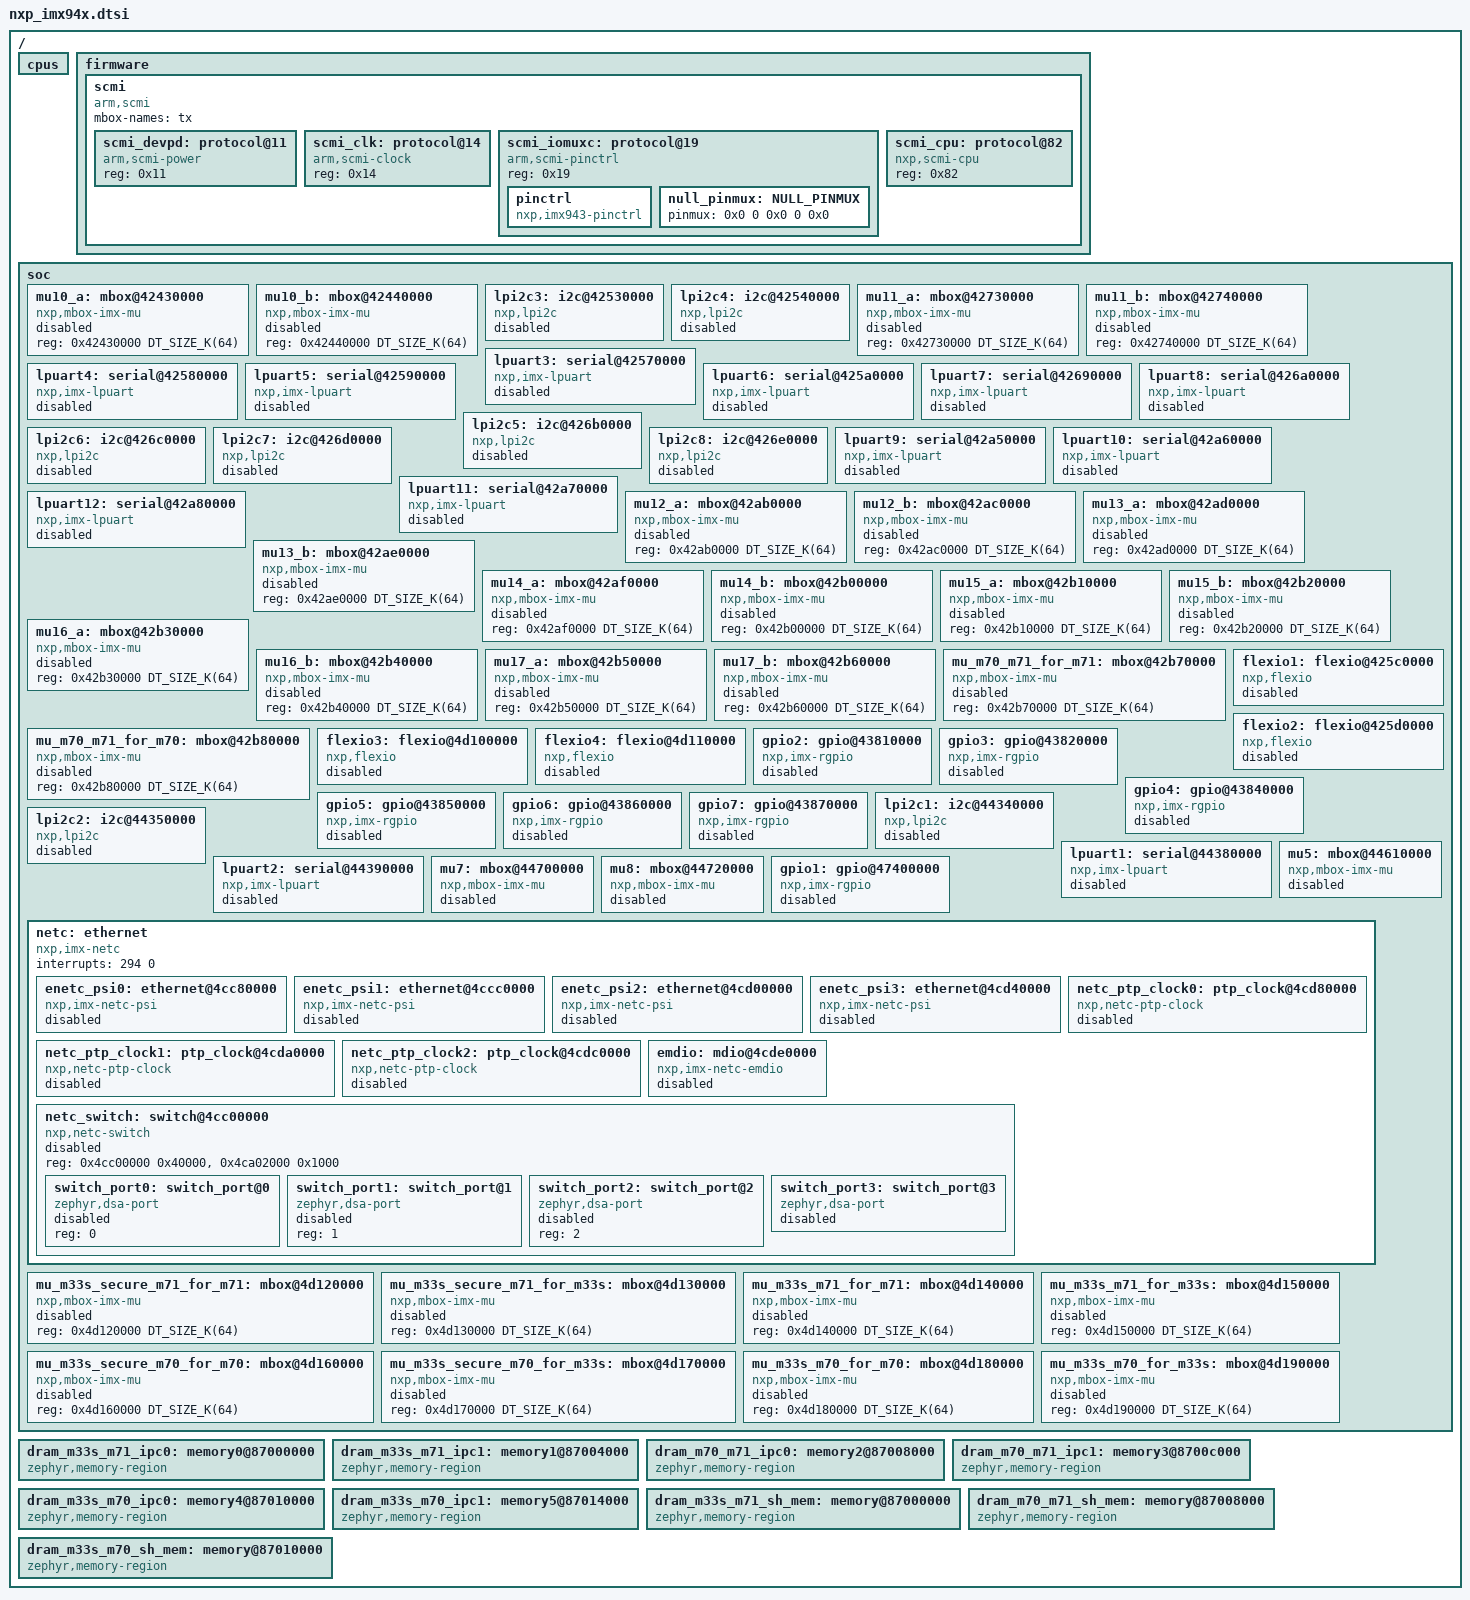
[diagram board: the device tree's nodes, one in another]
/*
 * Copyright 2025 NXP
 *
 * SPDX-License-Identifier: Apache-2.0
 */

#include <mem.h>
#include <dt-bindings/i2c/i2c.h>
#include <zephyr/dt-bindings/clock/imx943_clock.h>
#include <zephyr/dt-bindings/ethernet/dsa_tag_proto.h>
#include <zephyr/dt-bindings/gpio/gpio.h>
#include <zephyr/dt-bindings/memory-attr/memory-attr-arm.h>

/ {
	cpus {
		#address-cells = <1>;
		#size-cells = <0>;
	};

	firmware {
		scmi: scmi {
			compatible = "arm,scmi";
			mbox-names = "tx";

			#address-cells = <1>;
			#size-cells = <0>;

			scmi_devpd: protocol@11 {
				compatible = "arm,scmi-power";
				reg = <0x11>;
				#power-domain-cells = <1>;
			};

			scmi_clk: protocol@14 {
				compatible = "arm,scmi-clock";
				reg = <0x14>;
				#clock-cells = <1>;
			};

			scmi_iomuxc: protocol@19 {
				compatible = "arm,scmi-pinctrl";
				reg = <0x19>;

				pinctrl: pinctrl {
					compatible = "nxp,imx943-pinctrl", "nxp,imx93-pinctrl";
				};
				/*
				 * Use the NULL pinmux for the GPIO io port
				 * which is not available to
				 * make the driver to be easy.
				 */
				/omit-if-no-ref/ null_pinmux: NULL_PINMUX {
					pinmux = <0x0 0 0x0 0 0x0>;
				};
			};

			scmi_cpu: protocol@82 {
				compatible = "nxp,scmi-cpu";
				reg = <0x82>;
			};
		};
	};

	soc {
		mu10_a: mbox@42430000 {
			compatible = "nxp,mbox-imx-mu";
			reg = <0x42430000 DT_SIZE_K(64)>;
			#mbox-cells = <1>;
			status = "disabled";
		};

		mu10_b: mbox@42440000 {
			compatible = "nxp,mbox-imx-mu";
			reg = <0x42440000 DT_SIZE_K(64)>;
			#mbox-cells = <1>;
			status = "disabled";
		};

		lpi2c3: i2c@42530000 {
			compatible = "nxp,lpi2c";
			clock-frequency = <I2C_BITRATE_STANDARD>;
			#address-cells = <1>;
			#size-cells = <0>;
			reg = <0x42530000 0x4000>;
			interrupts = <67 0>;
			clocks = <&scmi_clk IMX943_CLK_LPI2C3>;
			status = "disabled";
		};

		lpi2c4: i2c@42540000 {
			compatible = "nxp,lpi2c";
			clock-frequency = <I2C_BITRATE_STANDARD>;
			#address-cells = <1>;
			#size-cells = <0>;
			reg = <0x42540000 0x4000>;
			interrupts = <68 0>;
			clocks = <&scmi_clk IMX943_CLK_LPI2C4>;
			status = "disabled";
		};

		mu11_a: mbox@42730000 {
			compatible = "nxp,mbox-imx-mu";
			reg = <0x42730000 DT_SIZE_K(64)>;
			#mbox-cells = <1>;
			status = "disabled";
		};

		mu11_b: mbox@42740000 {
			compatible = "nxp,mbox-imx-mu";
			reg = <0x42740000 DT_SIZE_K(64)>;
			#mbox-cells = <1>;
			status = "disabled";
		};

		lpuart3: serial@42570000 {
			compatible = "nxp,imx-lpuart", "nxp,lpuart";
			reg = <0x42570000 DT_SIZE_K(64)>;
			interrupts = <74 3>;
			clocks = <&scmi_clk IMX943_CLK_LPUART3>;
			status = "disabled";
		};

		lpuart4: serial@42580000 {
			compatible = "nxp,imx-lpuart", "nxp,lpuart";
			reg = <0x42580000 DT_SIZE_K(64)>;
			interrupts = <75 3>;
			clocks = <&scmi_clk IMX943_CLK_LPUART4>;
			status = "disabled";
		};

		lpuart5: serial@42590000 {
			compatible = "nxp,imx-lpuart", "nxp,lpuart";
			reg = <0x42590000 DT_SIZE_K(64)>;
			interrupts = <76 3>;
			clocks = <&scmi_clk IMX943_CLK_LPUART5>;
			status = "disabled";
		};

		lpuart6: serial@425a0000 {
			compatible = "nxp,imx-lpuart", "nxp,lpuart";
			reg = <0x425a0000 DT_SIZE_K(64)>;
			interrupts = <77 3>;
			clocks = <&scmi_clk IMX943_CLK_LPUART6>;
			status = "disabled";
		};

		lpuart7: serial@42690000 {
			compatible = "nxp,imx-lpuart", "nxp,lpuart";
			reg = <0x42690000 DT_SIZE_K(64)>;
			interrupts = <78 3>;
			clocks = <&scmi_clk IMX943_CLK_LPUART7>;
			status = "disabled";
		};

		lpuart8: serial@426a0000 {
			compatible = "nxp,imx-lpuart", "nxp,lpuart";
			reg = <0x426a0000 DT_SIZE_K(64)>;
			interrupts = <79 3>;
			clocks = <&scmi_clk IMX943_CLK_LPUART8>;
			status = "disabled";
		};

		lpi2c5: i2c@426b0000 {
			compatible = "nxp,lpi2c";
			clock-frequency = <I2C_BITRATE_STANDARD>;
			#address-cells = <1>;
			#size-cells = <0>;
			reg = <0x426b0000 0x4000>;
			interrupts = <108 0>;
			clocks = <&scmi_clk IMX943_CLK_LPI2C5>;
			status = "disabled";
		};

		lpi2c6: i2c@426c0000 {
			compatible = "nxp,lpi2c";
			clock-frequency = <I2C_BITRATE_STANDARD>;
			#address-cells = <1>;
			#size-cells = <0>;
			reg = <0x426c0000 0x4000>;
			interrupts = <109 0>;
			clocks = <&scmi_clk IMX943_CLK_LPI2C6>;
			status = "disabled";
		};

		lpi2c7: i2c@426d0000 {
			compatible = "nxp,lpi2c";
			clock-frequency = <I2C_BITRATE_STANDARD>;
			#address-cells = <1>;
			#size-cells = <0>;
			reg = <0x426d0000 0x4000>;
			interrupts = <110 0>;
			clocks = <&scmi_clk IMX943_CLK_LPI2C7>;
			status = "disabled";
		};

		lpi2c8: i2c@426e0000 {
			compatible = "nxp,lpi2c";
			clock-frequency = <I2C_BITRATE_STANDARD>;
			#address-cells = <1>;
			#size-cells = <0>;
			reg = <0x426e0000 0x4000>;
			interrupts = <111 0>;
			clocks = <&scmi_clk IMX943_CLK_LPI2C8>;
			status = "disabled";
		};

		lpuart9: serial@42a50000 {
			compatible = "nxp,imx-lpuart", "nxp,lpuart";
			reg = <0x42a50000 DT_SIZE_K(64)>;
			interrupts = <80 3>;
			clocks = <&scmi_clk IMX943_CLK_LPUART9>;
			status = "disabled";
		};

		lpuart10: serial@42a60000 {
			compatible = "nxp,imx-lpuart", "nxp,lpuart";
			reg = <0x42a60000 DT_SIZE_K(64)>;
			interrupts = <81 3>;
			clocks = <&scmi_clk IMX943_CLK_LPUART10>;
			status = "disabled";
		};

		lpuart11: serial@42a70000 {
			compatible = "nxp,imx-lpuart", "nxp,lpuart";
			reg = <0x42a70000 DT_SIZE_K(64)>;
			interrupts = <82 3>;
			clocks = <&scmi_clk IMX943_CLK_LPUART11>;
			status = "disabled";
		};

		lpuart12: serial@42a80000 {
			compatible = "nxp,imx-lpuart", "nxp,lpuart";
			reg = <0x42a80000 DT_SIZE_K(64)>;
			interrupts = <83 3>;
			clocks = <&scmi_clk IMX943_CLK_LPUART12>;
			status = "disabled";
		};

		mu12_a: mbox@42ab0000 {
			compatible = "nxp,mbox-imx-mu";
			reg = <0x42ab0000 DT_SIZE_K(64)>;
			#mbox-cells = <1>;
			status = "disabled";
		};

		mu12_b: mbox@42ac0000 {
			compatible = "nxp,mbox-imx-mu";
			reg = <0x42ac0000 DT_SIZE_K(64)>;
			#mbox-cells = <1>;
			status = "disabled";
		};

		mu13_a: mbox@42ad0000 {
			compatible = "nxp,mbox-imx-mu";
			reg = <0x42ad0000 DT_SIZE_K(64)>;
			#mbox-cells = <1>;
			status = "disabled";
		};

		mu13_b: mbox@42ae0000 {
			compatible = "nxp,mbox-imx-mu";
			reg = <0x42ae0000 DT_SIZE_K(64)>;
			#mbox-cells = <1>;
			status = "disabled";
		};

		mu14_a: mbox@42af0000 {
			compatible = "nxp,mbox-imx-mu";
			reg = <0x42af0000 DT_SIZE_K(64)>;
			#mbox-cells = <1>;
			status = "disabled";
		};

		mu14_b: mbox@42b00000 {
			compatible = "nxp,mbox-imx-mu";
			reg = <0x42b00000 DT_SIZE_K(64)>;
			#mbox-cells = <1>;
			status = "disabled";
		};

		mu15_a: mbox@42b10000 {
			compatible = "nxp,mbox-imx-mu";
			reg = <0x42b10000 DT_SIZE_K(64)>;
			#mbox-cells = <1>;
			status = "disabled";
		};

		mu15_b: mbox@42b20000 {
			compatible = "nxp,mbox-imx-mu";
			reg = <0x42b20000 DT_SIZE_K(64)>;
			#mbox-cells = <1>;
			status = "disabled";
		};

		mu16_a: mbox@42b30000 {
			compatible = "nxp,mbox-imx-mu";
			reg = <0x42b30000 DT_SIZE_K(64)>;
			#mbox-cells = <1>;
			status = "disabled";
		};

		mu16_b: mbox@42b40000 {
			compatible = "nxp,mbox-imx-mu";
			reg = <0x42b40000 DT_SIZE_K(64)>;
			#mbox-cells = <1>;
			status = "disabled";
		};

		mu17_a: mbox@42b50000 {
			compatible = "nxp,mbox-imx-mu";
			reg = <0x42b50000 DT_SIZE_K(64)>;
			#mbox-cells = <1>;
			status = "disabled";
		};

		mu17_b: mbox@42b60000 {
			compatible = "nxp,mbox-imx-mu";
			reg = <0x42b60000 DT_SIZE_K(64)>;
			#mbox-cells = <1>;
			status = "disabled";
		};

		mu_m70_m71_for_m71: mbox@42b70000 {
			compatible = "nxp,mbox-imx-mu";
			reg = <0x42b70000 DT_SIZE_K(64)>;
			#mbox-cells = <1>;
			status = "disabled";
		};

		mu_m70_m71_for_m70: mbox@42b80000 {
			compatible = "nxp,mbox-imx-mu";
			reg = <0x42b80000 DT_SIZE_K(64)>;
			#mbox-cells = <1>;
			status = "disabled";
		};

		flexio1: flexio@425c0000 {
			compatible = "nxp,flexio";
			reg = <0x425c0000 DT_SIZE_K(4)>;
			interrupts = <48 0>;
			clocks = <&scmi_clk IMX943_CLK_FLEXIO1>;
			status = "disabled";
		};

		flexio2: flexio@425d0000 {
			compatible = "nxp,flexio";
			reg = <0x425d0000 DT_SIZE_K(4)>;
			interrupts = <49 0>;
			clocks = <&scmi_clk IMX943_CLK_FLEXIO2>;
			status = "disabled";
		};

		flexio3: flexio@4d100000 {
			compatible = "nxp,flexio";
			reg = <0x4d100000 DT_SIZE_K(4)>;
			interrupts = <50 0>;
			clocks = <&scmi_clk IMX943_CLK_FLEXIO3>;
			status = "disabled";
		};

		flexio4: flexio@4d110000 {
			compatible = "nxp,flexio";
			reg = <0x4d110000 DT_SIZE_K(4)>;
			interrupts = <51 0>;
			clocks = <&scmi_clk IMX943_CLK_FLEXIO4>;
			status = "disabled";
		};

		gpio2: gpio@43810000 {
			compatible = "nxp,imx-rgpio";
			reg = <0x43810000 DT_SIZE_K(64)>;
			interrupts = <54 0>, <55 0>;
			gpio-controller;
			#gpio-cells = <2>;
			ngpios = <32>;
			status = "disabled";
		};

		gpio3: gpio@43820000 {
			compatible = "nxp,imx-rgpio";
			reg = <0x43820000 DT_SIZE_K(64)>;
			interrupts = <56 0>, <57 0>;
			gpio-controller;
			#gpio-cells = <2>;
			ngpios = <26>;
			status = "disabled";
		};

		gpio4: gpio@43840000 {
			compatible = "nxp,imx-rgpio";
			reg = <0x43840000 DT_SIZE_K(64)>;
			interrupts = <58 0>, <59 0>;
			gpio-controller;
			#gpio-cells = <2>;
			ngpios = <32>;
			status = "disabled";
		};

		gpio5: gpio@43850000 {
			compatible = "nxp,imx-rgpio";
			reg = <0x43850000 DT_SIZE_K(64)>;
			interrupts = <60 0>, <61 0>;
			gpio-controller;
			#gpio-cells = <2>;
			ngpios = <32>;
			status = "disabled";
		};

		gpio6: gpio@43860000 {
			compatible = "nxp,imx-rgpio";
			reg = <0x43860000 DT_SIZE_K(64)>;
			interrupts = <62 0>, <63 0>;
			gpio-controller;
			#gpio-cells = <2>;
			ngpios = <32>;
			status = "disabled";
		};

		gpio7: gpio@43870000 {
			compatible = "nxp,imx-rgpio";
			reg = <0x43870000 DT_SIZE_K(64)>;
			interrupts = <64 0>, <65 0>;
			gpio-controller;
			#gpio-cells = <2>;
			ngpios = <28>;
			gpio-reserved-ranges = <10 6>;
			status = "disabled";
		};

		lpi2c1: i2c@44340000 {
			compatible = "nxp,lpi2c";
			clock-frequency = <I2C_BITRATE_STANDARD>;
			#address-cells = <1>;
			#size-cells = <0>;
			reg = <0x44340000 0x4000>;
			interrupts = <15 0>;
			clocks = <&scmi_clk IMX943_CLK_LPI2C1>;
			status = "disabled";
		};

		lpi2c2: i2c@44350000 {
			compatible = "nxp,lpi2c";
			clock-frequency = <I2C_BITRATE_STANDARD>;
			#address-cells = <1>;
			#size-cells = <0>;
			reg = <0x44350000 0x4000>;
			interrupts = <16 0>;
			clocks = <&scmi_clk IMX943_CLK_LPI2C2>;
			status = "disabled";
		};

		lpuart1: serial@44380000 {
			compatible = "nxp,imx-lpuart", "nxp,lpuart";
			reg = <0x44380000 DT_SIZE_K(64)>;
			interrupts = <21 3>;
			clocks = <&scmi_clk IMX943_CLK_LPUART1>;
			status = "disabled";
		};

		lpuart2: serial@44390000 {
			compatible = "nxp,imx-lpuart", "nxp,lpuart";
			reg = <0x44390000 DT_SIZE_K(64)>;
			interrupts = <22 3>;
			clocks = <&scmi_clk IMX943_CLK_LPUART2>;
			status = "disabled";
		};

		mu5: mbox@44610000 {
			compatible = "nxp,mbox-imx-mu";
			reg = <0x44610000 DT_SIZE_K(64)>;
			interrupts = <122 0>;
			#mbox-cells = <1>;
			status = "disabled";
		};

		mu7: mbox@44700000 {
			compatible = "nxp,mbox-imx-mu";
			reg = <0x44700000 DT_SIZE_K(64)>;
			interrupts = <124 0>;
			#mbox-cells = <1>;
			status = "disabled";
		};

		mu8: mbox@44720000 {
			compatible = "nxp,mbox-imx-mu";
			reg = <0x44720000 DT_SIZE_K(64)>;
			interrupts = <273 0>;
			#mbox-cells = <1>;
			status = "disabled";
		};

		gpio1: gpio@47400000 {
			compatible = "nxp,imx-rgpio";
			reg = <0x47400000 DT_SIZE_K(64)>;
			interrupts = <12 0>, <13 0>;
			gpio-controller;
			#gpio-cells = <2>;
			ngpios = <16>;
			status = "disabled";
		};

		netc: ethernet {
			compatible = "nxp,imx-netc";
			interrupts = <294 0>;
			#address-cells = <1>;
			#size-cells = <1>;
			ranges;

			enetc_psi0: ethernet@4cc80000 {
				compatible = "nxp,imx-netc-psi";
				reg = <0x4cc80000 0x10000>,
				      <0x4cb00000 0x1000>;
				reg-names = "port", "pfconfig";
				mac-index = <0>;
				si-index = <0>;
				status = "disabled";
			};

			enetc_psi1: ethernet@4ccc0000 {
				compatible = "nxp,imx-netc-psi";
				reg = <0x4ccc0000 0x10000>,
				      <0x4cb40000 0x1000>;
				reg-names = "port", "pfconfig";
				mac-index = <1>;
				si-index = <1>;
				status = "disabled";
			};

			enetc_psi2: ethernet@4cd00000 {
				compatible = "nxp,imx-netc-psi";
				reg = <0x4cd00000 0x10000>,
				      <0x4cb80000 0x1000>;
				reg-names = "port", "pfconfig";
				mac-index = <2>;
				si-index = <2>;
				status = "disabled";
			};

			/* Internal port */
			enetc_psi3: ethernet@4cd40000 {
				compatible = "nxp,imx-netc-psi";
				reg = <0x4cd40000 0x10000>,
				      <0x4ca00000 0x1000>;
				reg-names = "port", "pfconfig";
				mac-index = <3>;
				si-index = <3>;
				phy-connection-type = "internal";
				status = "disabled";
			};

			netc_ptp_clock0: ptp_clock@4cd80000 {
				compatible = "nxp,netc-ptp-clock";
				reg = <0x4cd80000 0x10000>;
				clocks = <&scmi_clk IMX943_CLK_ENET>;
				status = "disabled";
			};

			netc_ptp_clock1: ptp_clock@4cda0000 {
				compatible = "nxp,netc-ptp-clock";
				reg = <0x4cda0000 0x10000>;
				clocks = <&scmi_clk IMX943_CLK_ENET>;
				status = "disabled";
			};

			netc_ptp_clock2: ptp_clock@4cdc0000 {
				compatible = "nxp,netc-ptp-clock";
				reg = <0x4cdc0000 0x10000>;
				clocks = <&scmi_clk IMX943_CLK_ENET>;
				status = "disabled";
			};

			emdio: mdio@4cde0000 {
				compatible = "nxp,imx-netc-emdio";
				reg = <0x4cde0000 0x10000>,
					<0x4cbc0000 0x40000>;
				reg-names = "basic", "pfconfig";
				clocks = <&scmi_clk IMX943_CLK_ENET>;
				#address-cells = <1>;
				#size-cells = <0>;
				status = "disabled";
			};

			netc_switch: switch@4cc00000 {
				compatible = "nxp,netc-switch";
				reg = <0x4cc00000 0x40000>,
				      <0x4ca02000 0x1000>;
				reg-names = "base", "pfconfig";
				status = "disabled";
				#address-cells = <1>;
				#size-cells = <0>;

				switch_port0: switch_port@0 {
					compatible = "zephyr,dsa-port";
					reg = <0>;
					status = "disabled";
				};

				switch_port1: switch_port@1 {
					compatible = "zephyr,dsa-port";
					reg = <1>;
					status = "disabled";
				};

				/* Parallel interface is muxed with enetc_psi0. */
				switch_port2: switch_port@2 {
					compatible = "zephyr,dsa-port";
					reg = <2>;
					status = "disabled";
				};

				/* Internal port */
				switch_port3: switch_port@3 {
					compatible = "zephyr,dsa-port";
					reg = <3>;
					ethernet = <&enetc_psi3>;
					phy-connection-type = "internal";
					dsa-tag-protocol = <DSA_TAG_PROTO_NETC>;
					status = "disabled";
				};
			};
		};

		mu_m33s_secure_m71_for_m71: mbox@4d120000 {
			compatible = "nxp,mbox-imx-mu";
			reg = <0x4d120000 DT_SIZE_K(64)>;
			#mbox-cells = <1>;
			status = "disabled";
		};

		mu_m33s_secure_m71_for_m33s: mbox@4d130000 {
			compatible = "nxp,mbox-imx-mu";
			reg = <0x4d130000 DT_SIZE_K(64)>;
			#mbox-cells = <1>;
			status = "disabled";
		};

		mu_m33s_m71_for_m71: mbox@4d140000 {
			compatible = "nxp,mbox-imx-mu";
			reg = <0x4d140000 DT_SIZE_K(64)>;
			#mbox-cells = <1>;
			status = "disabled";
		};

		mu_m33s_m71_for_m33s: mbox@4d150000 {
			compatible = "nxp,mbox-imx-mu";
			reg = <0x4d150000 DT_SIZE_K(64)>;
			#mbox-cells = <1>;
			status = "disabled";
		};

		mu_m33s_secure_m70_for_m70: mbox@4d160000 {
			compatible = "nxp,mbox-imx-mu";
			reg = <0x4d160000 DT_SIZE_K(64)>;
			#mbox-cells = <1>;
			status = "disabled";
		};

		mu_m33s_secure_m70_for_m33s: mbox@4d170000 {
			compatible = "nxp,mbox-imx-mu";
			reg = <0x4d170000 DT_SIZE_K(64)>;
			#mbox-cells = <1>;
			status = "disabled";
		};

		mu_m33s_m70_for_m70: mbox@4d180000 {
			compatible = "nxp,mbox-imx-mu";
			reg = <0x4d180000 DT_SIZE_K(64)>;
			#mbox-cells = <1>;
			status = "disabled";
		};

		mu_m33s_m70_for_m33s: mbox@4d190000 {
			compatible = "nxp,mbox-imx-mu";
			reg = <0x4d190000 DT_SIZE_K(64)>;
			#mbox-cells = <1>;
			status = "disabled";
		};
	};
	/* Define memory regions for IPC between m33s and m71 */
	dram_m33s_m71_ipc0: memory0@87000000 {
		compatible = "zephyr,memory-region", "mmio-sram";
		reg = <0x87000000 DT_SIZE_K(16)>;
		zephyr,memory-region="DRAM_M33S_M71_IPC0";
		zephyr,memory-attr = <(DT_MEM_ARM(ATTR_MPU_RAM_NOCACHE))>;
	};

	dram_m33s_m71_ipc1: memory1@87004000 {
		compatible = "zephyr,memory-region", "mmio-sram";
		reg = <0x87004000 DT_SIZE_K(16)>;
		zephyr,memory-region="DRAM_M33S_M71_IPC1";
		zephyr,memory-attr = <(DT_MEM_ARM(ATTR_MPU_RAM_NOCACHE))>;
	};

	/* Define memory regions for IPC between m70 and m71 */
	dram_m70_m71_ipc0: memory2@87008000 {
		compatible = "zephyr,memory-region", "mmio-sram";
		reg = <0x87008000 DT_SIZE_K(16)>;
		zephyr,memory-region="DRAM_M70_M71_IPC0";
		zephyr,memory-attr = <(DT_MEM_ARM(ATTR_MPU_RAM_NOCACHE))>;
	};

	dram_m70_m71_ipc1: memory3@8700c000 {
		compatible = "zephyr,memory-region", "mmio-sram";
		reg = <0x8700c000 DT_SIZE_K(16)>;
		zephyr,memory-region="DRAM_M70_M71_IPC1";
		zephyr,memory-attr = <(DT_MEM_ARM(ATTR_MPU_RAM_NOCACHE))>;
	};

	/* Define memory regions for IPC between m33s and m70 */
	dram_m33s_m70_ipc0: memory4@87010000 {
		compatible = "zephyr,memory-region", "mmio-sram";
		reg = <0x87010000 DT_SIZE_K(16)>;
		zephyr,memory-region="DRAM_M33S_M70_IPC0";
		zephyr,memory-attr = <(DT_MEM_ARM(ATTR_MPU_RAM_NOCACHE))>;
	};

	dram_m33s_m70_ipc1: memory5@87014000 {
		compatible = "zephyr,memory-region", "mmio-sram";
		reg = <0x87014000 DT_SIZE_K(16)>;
		zephyr,memory-region="DRAM_M33S_M70_IPC1";
		zephyr,memory-attr = <(DT_MEM_ARM(ATTR_MPU_RAM_NOCACHE))>;
	};

	/* Define memory regions for IPC between m33s and m71 */
	dram_m33s_m71_sh_mem: memory@87000000 {
		compatible = "zephyr,memory-region", "mmio-sram";
		reg = <0x87000000 DT_SIZE_K(32)>;
		zephyr,memory-region="DRAM_M33S_M71_SH_MEM";
		zephyr,memory-attr = <(DT_MEM_ARM(ATTR_MPU_RAM_NOCACHE))>;
	};

	/* Define memory regions for IPC between m70 and m71 */
	dram_m70_m71_sh_mem: memory@87008000 {
		compatible = "zephyr,memory-region", "mmio-sram";
		reg = <0x87008000 DT_SIZE_K(32)>;
		zephyr,memory-region="DRAM_M70_M71_SH_MEM";
		zephyr,memory-attr = <(DT_MEM_ARM(ATTR_MPU_RAM_NOCACHE))>;
	};

	/* Define memory regions for IPC between m33s and m70 */
	dram_m33s_m70_sh_mem: memory@87010000 {
		compatible = "zephyr,memory-region", "mmio-sram";
		reg = <0x87010000 DT_SIZE_K(32)>;
		zephyr,memory-region="DRAM_M33S_M70_SH_MEM";
		zephyr,memory-attr = <(DT_MEM_ARM(ATTR_MPU_RAM_NOCACHE))>;
	};
};

/*
 * GPIO pinmux options. These options define the pinmux settings
 * for GPIO ports on the package, so that the GPIO driver can
 * select GPIO mux options during GPIO configuration.
 */

&gpio1{
	pinmux = <&iomuxc_i2c1_scl_gpio_io_gpio1_io0>,
		<&iomuxc_i2c1_sda_gpio_io_gpio1_io1>,
		<&iomuxc_i2c2_scl_gpio_io_gpio1_io2>,
		<&iomuxc_i2c2_sda_gpio_io_gpio1_io3>,
		<&iomuxc_uart1_rxd_gpio_io_gpio1_io4>,
		<&iomuxc_uart1_txd_gpio_io_gpio1_io5>,
		<&iomuxc_uart2_rxd_gpio_io_gpio1_io6>,
		<&iomuxc_uart2_txd_gpio_io_gpio1_io7>,
		<&iomuxc_pdm_clk_gpio_io_gpio1_io8>,
		<&iomuxc_pdm_bit_stream0_gpio_io_gpio1_io9>,
		<&iomuxc_pdm_bit_stream1_gpio_io_gpio1_io10>,
		<&iomuxc_sai1_txfs_gpio_io_gpio1_io11>,
		<&iomuxc_sai1_txc_gpio_io_gpio1_io12>,
		<&iomuxc_sai1_txd0_gpio_io_gpio1_io13>,
		<&iomuxc_sai1_rxd0_gpio_io_gpio1_io14>,
		<&iomuxc_wdog_any_gpio_io_gpio1_io15>;
};

&gpio2{
	pinmux = <&iomuxc_gpio_io00_gpio_io_gpio2_io0>,
		<&iomuxc_gpio_io01_gpio_io_gpio2_io1>,
		<&iomuxc_gpio_io02_gpio_io_gpio2_io2>,
		<&iomuxc_gpio_io03_gpio_io_gpio2_io3>,
		<&iomuxc_gpio_io04_gpio_io_gpio2_io4>,
		<&iomuxc_gpio_io05_gpio_io_gpio2_io5>,
		<&iomuxc_gpio_io06_gpio_io_gpio2_io6>,
		<&iomuxc_gpio_io07_gpio_io_gpio2_io7>,
		<&iomuxc_gpio_io08_gpio_io_gpio2_io8>,
		<&iomuxc_gpio_io09_gpio_io_gpio2_io9>,
		<&iomuxc_gpio_io10_gpio_io_gpio2_io10>,
		<&iomuxc_gpio_io11_gpio_io_gpio2_io11>,
		<&iomuxc_gpio_io12_gpio_io_gpio2_io12>,
		<&iomuxc_gpio_io13_gpio_io_gpio2_io13>,
		<&iomuxc_gpio_io14_gpio_io_gpio2_io14>,
		<&iomuxc_gpio_io15_gpio_io_gpio2_io15>,
		<&iomuxc_gpio_io16_gpio_io_gpio2_io16>,
		<&iomuxc_gpio_io17_gpio_io_gpio2_io17>,
		<&iomuxc_gpio_io18_gpio_io_gpio2_io18>,
		<&iomuxc_gpio_io19_gpio_io_gpio2_io19>,
		<&iomuxc_gpio_io20_gpio_io_gpio2_io20>,
		<&iomuxc_gpio_io21_gpio_io_gpio2_io21>,
		<&iomuxc_gpio_io22_gpio_io_gpio2_io22>,
		<&iomuxc_gpio_io23_gpio_io_gpio2_io23>,
		<&iomuxc_gpio_io24_gpio_io_gpio2_io24>,
		<&iomuxc_gpio_io25_gpio_io_gpio2_io25>,
		<&iomuxc_gpio_io26_gpio_io_gpio2_io26>,
		<&iomuxc_gpio_io27_gpio_io_gpio2_io27>,
		<&iomuxc_gpio_io28_gpio_io_gpio2_io28>,
		<&iomuxc_gpio_io29_gpio_io_gpio2_io29>,
		<&iomuxc_gpio_io30_gpio_io_gpio2_io30>,
		<&iomuxc_gpio_io31_gpio_io_gpio2_io31>;
};

&gpio3{
	pinmux = <&iomuxc_gpio_io32_gpio_io_gpio3_io0>,
		<&iomuxc_gpio_io33_gpio_io_gpio3_io1>,
		<&iomuxc_gpio_io34_gpio_io_gpio3_io2>,
		<&iomuxc_gpio_io35_gpio_io_gpio3_io3>,
		<&iomuxc_gpio_io36_gpio_io_gpio3_io4>,
		<&iomuxc_gpio_io37_gpio_io_gpio3_io5>,
		<&iomuxc_gpio_io38_gpio_io_gpio3_io6>,
		<&iomuxc_gpio_io39_gpio_io_gpio3_io7>,
		<&iomuxc_gpio_io40_gpio_io_gpio3_io8>,
		<&iomuxc_gpio_io41_gpio_io_gpio3_io9>,
		<&iomuxc_gpio_io42_gpio_io_gpio3_io10>,
		<&iomuxc_gpio_io43_gpio_io_gpio3_io11>,
		<&iomuxc_gpio_io44_gpio_io_gpio3_io12>,
		<&iomuxc_gpio_io45_gpio_io_gpio3_io13>,
		<&iomuxc_gpio_io46_gpio_io_gpio3_io14>,
		<&iomuxc_gpio_io47_gpio_io_gpio3_io15>,
		<&iomuxc_gpio_io48_gpio_io_gpio3_io16>,
		<&iomuxc_gpio_io49_gpio_io_gpio3_io17>,
		<&iomuxc_gpio_io50_gpio_io_gpio3_io18>,
		<&iomuxc_gpio_io51_gpio_io_gpio3_io19>,
		<&iomuxc_gpio_io52_gpio_io_gpio3_io20>,
		<&iomuxc_gpio_io53_gpio_io_gpio3_io21>,
		<&iomuxc_gpio_io54_gpio_io_gpio3_io22>,
		<&iomuxc_gpio_io55_gpio_io_gpio3_io23>,
		<&iomuxc_gpio_io56_gpio_io_gpio3_io24>,
		<&iomuxc_gpio_io57_gpio_io_gpio3_io25>;
};

&gpio4{
	pinmux = <&iomuxc_ccm_clko1_gpio_io_gpio4_io0>,
		<&iomuxc_ccm_clko2_gpio_io_gpio4_io1>,
		<&iomuxc_ccm_clko3_gpio_io_gpio4_io2>,
		<&iomuxc_ccm_clko4_gpio_io_gpio4_io3>,
		<&iomuxc_dap_tdi_gpio_io_gpio4_io4>,
		<&iomuxc_dap_tms_swdio_gpio_io_gpio4_io5>,
		<&iomuxc_dap_tclk_swclk_gpio_io_gpio4_io6>,
		<&iomuxc_dap_tdo_traceswo_gpio_io_gpio4_io7>,
		<&iomuxc_sd1_clk_gpio_io_gpio4_io8>,
		<&iomuxc_sd1_cmd_gpio_io_gpio4_io9>,
		<&iomuxc_sd1_data0_gpio_io_gpio4_io10>,
		<&iomuxc_sd1_data1_gpio_io_gpio4_io11>,
		<&iomuxc_sd1_data2_gpio_io_gpio4_io12>,
		<&iomuxc_sd1_data3_gpio_io_gpio4_io13>,
		<&iomuxc_sd1_data4_gpio_io_gpio4_io14>,
		<&iomuxc_sd1_data5_gpio_io_gpio4_io15>,
		<&iomuxc_sd1_data6_gpio_io_gpio4_io16>,
		<&iomuxc_sd1_data7_gpio_io_gpio4_io17>,
		<&iomuxc_sd1_strobe_gpio_io_gpio4_io18>,
		<&iomuxc_sd2_vselect_gpio_io_gpio4_io19>,
		<&iomuxc_sd2_cd_b_gpio_io_gpio4_io20>,
		<&iomuxc_sd2_clk_gpio_io_gpio4_io21>,
		<&iomuxc_sd2_cmd_gpio_io_gpio4_io22>,
		<&iomuxc_sd2_data0_gpio_io_gpio4_io23>,
		<&iomuxc_sd2_data1_gpio_io_gpio4_io24>,
		<&iomuxc_sd2_data2_gpio_io_gpio4_io25>,
		<&iomuxc_sd2_data3_gpio_io_gpio4_io26>,
		<&iomuxc_sd2_reset_b_gpio_io_gpio4_io27>,
		<&iomuxc_sd2_gpio0_gpio_io_gpio4_io28>,
		<&iomuxc_sd2_gpio1_gpio_io_gpio4_io29>,
		<&iomuxc_sd2_gpio2_gpio_io_gpio4_io30>,
		<&iomuxc_sd2_gpio3_gpio_io_gpio4_io31>;
};

&gpio5{
	pinmux = <&iomuxc_eth0_txd0_gpio_io_gpio5_io0>,
		<&iomuxc_eth0_txd1_gpio_io_gpio5_io1>,
		<&iomuxc_eth0_tx_en_gpio_io_gpio5_io2>,
		<&iomuxc_eth0_tx_clk_gpio_io_gpio5_io3>,
		<&iomuxc_eth0_rxd0_gpio_io_gpio5_io4>,
		<&iomuxc_eth0_rxd1_gpio_io_gpio5_io5>,
		<&iomuxc_eth0_rx_dv_gpio_io_gpio5_io6>,
		<&iomuxc_eth0_txd2_gpio_io_gpio5_io7>,
		<&iomuxc_eth0_txd3_gpio_io_gpio5_io8>,
		<&iomuxc_eth0_rxd2_gpio_io_gpio5_io9>,
		<&iomuxc_eth0_rxd3_gpio_io_gpio5_io10>,
		<&iomuxc_eth0_rx_clk_gpio_io_gpio5_io11>,
		<&iomuxc_eth0_rx_er_gpio_io_gpio5_io12>,
		<&iomuxc_eth0_tx_er_gpio_io_gpio5_io13>,
		<&iomuxc_eth0_crs_gpio_io_gpio5_io14>,
		<&iomuxc_eth0_col_gpio_io_gpio5_io15>,
		<&iomuxc_eth1_txd0_gpio_io_gpio5_io16>,
		<&iomuxc_eth1_txd1_gpio_io_gpio5_io17>,
		<&iomuxc_eth1_tx_en_gpio_io_gpio5_io18>,
		<&iomuxc_eth1_tx_clk_gpio_io_gpio5_io19>,
		<&iomuxc_eth1_rxd0_gpio_io_gpio5_io20>,
		<&iomuxc_eth1_rxd1_gpio_io_gpio5_io21>,
		<&iomuxc_eth1_rx_dv_gpio_io_gpio5_io22>,
		<&iomuxc_eth1_txd2_gpio_io_gpio5_io23>,
		<&iomuxc_eth1_txd3_gpio_io_gpio5_io24>,
		<&iomuxc_eth1_rxd2_gpio_io_gpio5_io25>,
		<&iomuxc_eth1_rxd3_gpio_io_gpio5_io26>,
		<&iomuxc_eth1_rx_clk_gpio_io_gpio5_io27>,
		<&iomuxc_eth1_rx_er_gpio_io_gpio5_io28>,
		<&iomuxc_eth1_tx_er_gpio_io_gpio5_io29>,
		<&iomuxc_eth1_crs_gpio_io_gpio5_io30>,
		<&iomuxc_eth1_col_gpio_io_gpio5_io31>;
};

&gpio6{
	pinmux = <&iomuxc_eth2_mdc_gpio1_gpio_io_gpio6_io0>,
		<&iomuxc_eth2_mdio_gpio2_gpio_io_gpio6_io1>,
		<&iomuxc_eth2_txd3_gpio_io_gpio6_io2>,
		<&iomuxc_eth2_txd2_gpio_io_gpio6_io3>,
		<&iomuxc_eth2_txd1_gpio_io_gpio6_io4>,
		<&iomuxc_eth2_txd0_gpio_io_gpio6_io5>,
		<&iomuxc_eth2_tx_ctl_gpio_io_gpio6_io6>,
		<&iomuxc_eth2_tx_clk_gpio_io_gpio6_io7>,
		<&iomuxc_eth2_rx_ctl_gpio_io_gpio6_io8>,
		<&iomuxc_eth2_rx_clk_gpio_io_gpio6_io9>,
		<&iomuxc_eth2_rxd0_gpio_io_gpio6_io10>,
		<&iomuxc_eth2_rxd1_gpio_io_gpio6_io11>,
		<&iomuxc_eth2_rxd2_gpio_io_gpio6_io12>,
		<&iomuxc_eth2_rxd3_gpio_io_gpio6_io13>,
		<&iomuxc_eth3_mdc_gpio1_gpio_io_gpio6_io14>,
		<&iomuxc_eth3_mdio_gpio2_gpio_io_gpio6_io15>,
		<&iomuxc_eth3_txd3_gpio_io_gpio6_io16>,
		<&iomuxc_eth3_txd2_gpio_io_gpio6_io17>,
		<&iomuxc_eth3_txd1_gpio_io_gpio6_io18>,
		<&iomuxc_eth3_txd0_gpio_io_gpio6_io19>,
		<&iomuxc_eth3_tx_ctl_gpio_io_gpio6_io20>,
		<&iomuxc_eth3_tx_clk_gpio_io_gpio6_io21>,
		<&iomuxc_eth3_rx_ctl_gpio_io_gpio6_io22>,
		<&iomuxc_eth3_rx_clk_gpio_io_gpio6_io23>,
		<&iomuxc_eth3_rxd0_gpio_io_gpio6_io24>,
		<&iomuxc_eth3_rxd1_gpio_io_gpio6_io25>,
		<&iomuxc_eth3_rxd2_gpio_io_gpio6_io26>,
		<&iomuxc_eth3_rxd3_gpio_io_gpio6_io27>,
		<&iomuxc_eth4_mdc_gpio1_gpio_io_gpio6_io28>,
		<&iomuxc_eth4_mdio_gpio2_gpio_io_gpio6_io29>,
		<&iomuxc_eth4_tx_clk_gpio_io_gpio6_io30>,
		<&iomuxc_eth4_tx_ctl_gpio_io_gpio6_io31>;
};

&gpio7{
	pinmux = <&iomuxc_eth4_txd0_gpio_io_gpio7_io0>,
		<&iomuxc_eth4_txd1_gpio_io_gpio7_io1>,
		<&iomuxc_eth4_txd2_gpio_io_gpio7_io2>,
		<&iomuxc_eth4_txd3_gpio_io_gpio7_io3>,
		<&iomuxc_eth4_rxd0_gpio_io_gpio7_io4>,
		<&iomuxc_eth4_rxd1_gpio_io_gpio7_io5>,
		<&iomuxc_eth4_rxd2_gpio_io_gpio7_io6>,
		<&iomuxc_eth4_rxd3_gpio_io_gpio7_io7>,
		<&iomuxc_eth4_rx_ctl_gpio_io_gpio7_io8>,
		<&iomuxc_eth4_rx_clk_gpio_io_gpio7_io9>,
		<&null_pinmux>,
		<&null_pinmux>,
		<&null_pinmux>,
		<&null_pinmux>,
		<&null_pinmux>,
		<&null_pinmux>,
		<&iomuxc_xspi1_data0_gpio_io_gpio7_io16>,
		<&iomuxc_xspi1_data1_gpio_io_gpio7_io17>,
		<&iomuxc_xspi1_data2_gpio_io_gpio7_io18>,
		<&iomuxc_xspi1_data3_gpio_io_gpio7_io19>,
		<&iomuxc_xspi1_data4_gpio_io_gpio7_io20>,
		<&iomuxc_xspi1_data5_gpio_io_gpio7_io21>,
		<&iomuxc_xspi1_data6_gpio_io_gpio7_io22>,
		<&iomuxc_xspi1_data7_gpio_io_gpio7_io23>,
		<&iomuxc_xspi1_dqs_gpio_io_gpio7_io24>,
		<&iomuxc_xspi1_sclk_gpio_io_gpio7_io25>,
		<&iomuxc_xspi1_ss0_b_gpio_io_gpio7_io26>,
		<&iomuxc_xspi1_ss1_b_gpio_io_gpio7_io27>;
};
